# nrf54h20_enga_sysctrl register map
Vendor: Nordic Semiconductor; Series: nRF54h; File version: 1
Registers are 32-bit, read-write, reset 0x0 unless marked. A register's access mark holds for its fields unless they carry their own. Offsets are from the block's base; [hi:lo] are bit positions; lines under a group give offsets from that group; {n}, {i} and the like mark numbered series.

## PCGCS110_S — PCGCSlave 0
Base 0x5F08E000
Same registers: PCGCS120_S 0x5F8EA000, PCGCS121_S 0x5F8EB000, PCGCS122_S 0x5F8EC000, PCGCS130_S 0x5F90E000, PCGCS131_S 0x5F93C000, PCGCS132_S 0x5F94E000, PCGCS133_S 0x5F98E000, PCGCS134_S 0x5F99E000, PCGCS135_S 0x5F9AE000, PCGCS136_S 0x5F9BE000, PCGCS137_S 0x5F9CE000, PCGCS138_S 0x5F9DE000
{0xC00+4i} PENALTY[{i}] (i=0..1) — Description collection: Penalty level for power/clock pair n
  [7:0] PENALTY — Penalty level
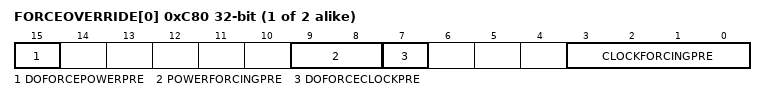
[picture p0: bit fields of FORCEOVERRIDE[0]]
{0xC80+4i} FORCEOVERRIDE[{i}] (i=0..1) — Description collection: Force override of power/clock pair n
  [15] DOFORCEPOWERPRE, [9:8] POWERFORCINGPRE, [7] DOFORCECLOCKPRE, [3:0] CLOCKFORCINGPRE

## PCGCM110_S — PCGC Master 0
Base 0x5F08F000
Same registers: PCGCM120_S 0x5F8CF000, PCGCM121_S 0x5F8ED000, PCGCM130_S 0x5F93D000, PCGCM131_S 0x5F93F000, PCGCM132_S 0x5F94F000, PCGCM133_S 0x5F98F000, PCGCM134_S 0x5F99F000, PCGCM135_S 0x5F9AF000, PCGCM136_S 0x5F9BF000, PCGCM137_S 0x5F9CF000, PCGCM138_S 0x5F9DF000
{0xE0+4i} SETPWRCONTHRESHOLDBASE[{i}] (i=0..2) — Description collection: Set power consumption threshold base for power source / regulator n
  [3:0] SETPWRCONTHRESHOLDBASE
{0x100+4i} SETPOWERCONSUMPTIONBASE[{i}] (i=0..1) — Description collection: Set power consumption base for power/clock pair n
  [3:0] POWERREQUIREMENT
0xC00 UNLOCKBACKDOORS
  [15:0] UNLOCKBACKDOORS — Write: 0x00009375 to lock/unlock backdoors Read: 0x00000001 if backdoors is enabled Read: 0x00000000 if backdoors is disabled
0xC04 ENABLEPOWERREGFORCE
  [2:0] ENABLEPOWERREGFORCE
0xC08 POWERREGFORCE — Force reg
  [2:0] POWERREGFORCEREG
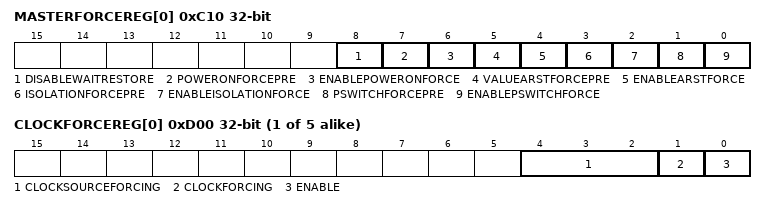
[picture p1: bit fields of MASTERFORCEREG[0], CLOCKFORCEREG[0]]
{0xC10+4i} MASTERFORCEREG[{i}] (i=0..0) — Description collection: Force reg
  [8] DISABLEWAITRESTORE — Turn off waiting for arst deactivation before retention restore
    1=Disable (Turn off waiting for arst deactivation before retention restore); 0=Enable (Wait for arst deactivation before retention restore)
  [7] POWERONFORCEPRE
  [6] ENABLEPOWERONFORCE
  [5] VALUEARSTFORCEPRE
  [4] ENABLEARSTFORCE
  [3] ISOLATIONFORCEPRE
  [2] ENABLEISOLATIONFORCE
  [1] PSWITCHFORCEPRE
  [0] ENABLEPSWITCHFORCE
{0xD00+4i} CLOCKFORCEREG[{i}] (i=0..4) — Description collection: Force clock n
  [4:2] CLOCKSOURCEFORCING
  [1] CLOCKFORCING
  [0] ENABLE — Enable clock forcing

## PPIB110_S — PPIB APB registers 0
Base 0x5F098000
Same registers: PPIB120_S 0x5F8EE000, PPIB121_S 0x5F8EF000, PPIB130_S 0x5F925000, PPIB131_S 0x5F926000, PPIB132_S 0x5F98D000, PPIB133_S 0x5F99D000, PPIB134_S 0x5F9AD000, PPIB135_S 0x5F9BD000, PPIB136_S 0x5F9CD000, PPIB137_S 0x5F9DD000
{0x0+4i} TASKS_SEND[{i}] (i=0..31) wo — Description collection: This task is unused, but the PPIB provides the SUBSCRIBE task to connect SEND [n] task.
  [0] TASKS_SEND — This task is unused, but the PPIB provides the SUBSCRIBE task to connect SEND [n] task.
    1=Trigger task
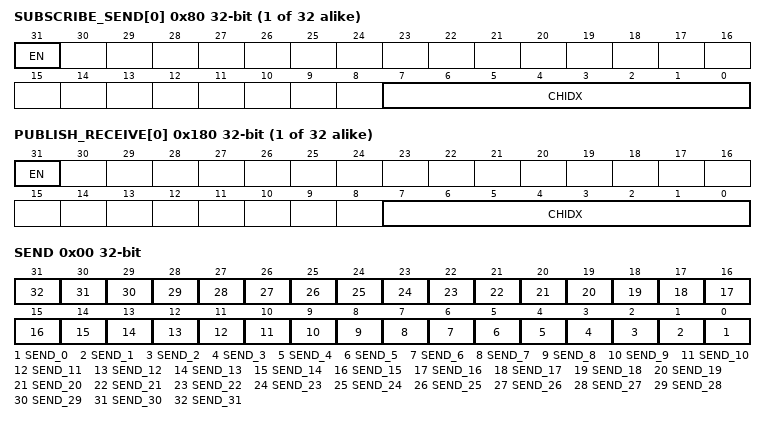
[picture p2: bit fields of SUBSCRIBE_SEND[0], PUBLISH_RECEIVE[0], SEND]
{0x80+4i} SUBSCRIBE_SEND[{i}] (i=0..31) — Description collection: Subscribe configuration for task SEND[n]
  [31] EN
    0=Disabled (Disable subscription); 1=Enabled (Enable subscription)
  [7:0] CHIDX — DPPI channel that task SEND[n] will subscribe to
{0x100+4i} EVENTS_RECEIVE[{i}] (i=0..31) — Description collection: This event is unused, but the PPIB provides the PUBLISH event to connect RECEIVE [n] event.
  [0] EVENTS_RECEIVE — This event is unused, but the PPIB provides the PUBLISH event to connect RECEIVE [n] event.
    0=NotGenerated (Event not generated); 1=Generated (Event generated)
{0x180+4i} PUBLISH_RECEIVE[{i}] (i=0..31) — Description collection: Publish configuration for event RECEIVE[n]
  [31] EN
    0=Disabled (Disable publishing); 1=Enabled (Enable publishing)
  [7:0] CHIDX — DPPI channel that event RECEIVE[n] will publish to
0x400 OVERFLOW group — Unspecified
  0x00 SEND — The task overflow for SEND tasks using SUBSCRIBE_SEND. Write 0 to clear.
    [all] fields
      1=Overflow (Task overflow is happened.); 0=NoOverflow (Task overflow is not happened.)
    [n] SEND_{n} (n=0..31) — The status for tasks overflow at SUBSCRIBE_SEND[{n}].
